# DMASS0_ECC_AGGR_0_ECCAGGR register map
Vendor: Texas Instruments
Peripheral module from a debugger description file (folder am62x).
Registers are 32-bit, access not given, reset 0x0 unless marked. A register's access mark holds for its fields unless they carry their own. Offsets are as the file gives them; lines under a group give offsets from that group; [hi:lo] are bit positions; {n}, {i} and the like mark numbered series; 'fields as' and 'values as' point back to an identical list; <NAME> marks a mode.

## DMASS0_ECC_AGGR_0_ECCAGGR
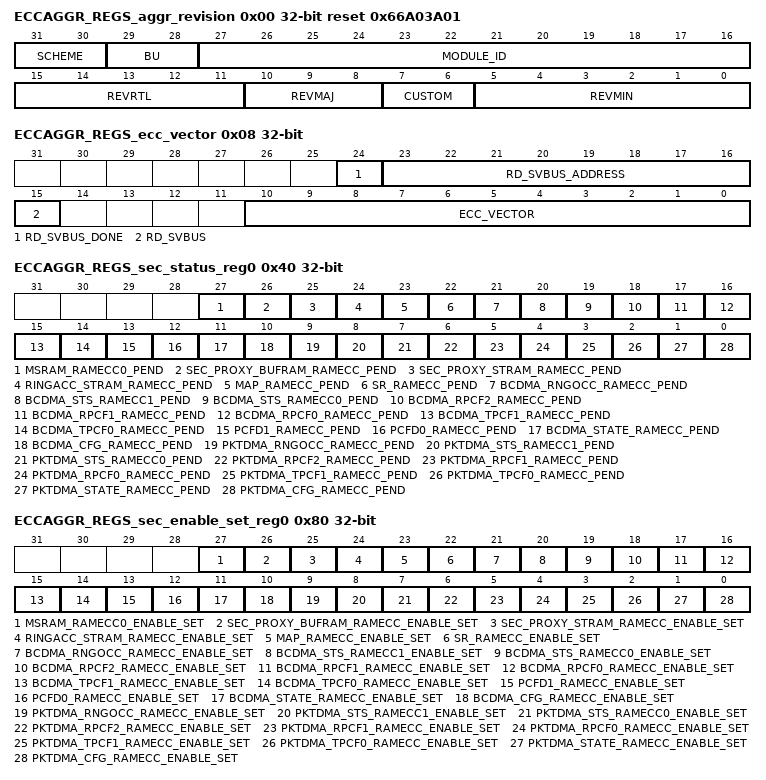
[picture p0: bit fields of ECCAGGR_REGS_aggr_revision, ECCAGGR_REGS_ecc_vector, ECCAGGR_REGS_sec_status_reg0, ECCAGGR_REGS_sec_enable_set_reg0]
0x00 ECCAGGR_REGS_aggr_revision ro reset 0x66A03A01 — Revision parameters
  [31:30] SCHEME
  [29:28] BU
  [27:16] MODULE_ID
  [15:11] REVRTL — RTL version
  [10:8] REVMAJ — Major version
  [7:6] CUSTOM — Custom version
  [5:0] REVMIN — Minor version
0x08 ECCAGGR_REGS_ecc_vector — ECC Vector Register
  [24] RD_SVBUS_DONE — Status to indicate if read on serial VBUS is complete, write of any value will clear this bit. (access R/W1TC)
  [23:16] RD_SVBUS_ADDRESS rw — Read address
  [15] RD_SVBUS — Write 1 to trigger a read on the serial VBUS (access R/W1TS)
  [10:0] ECC_VECTOR rw — Value written to select the corresponding ECC RAM for control or status
0x0C ECCAGGR_REGS_misc_status ro reset 0x1C — Misc Status
  [10:0] NUM_RAMS — Indicates the number of RAMS serviced by the ECC aggregator
0x10 ECCAGGR_REGS_reserved_svbus rw — Reference other documents that contain the ECC RAM wrapper and EDC controller serial vbus register sets.
  [31:0] DATA — Serial VBUS register data
0x3C ECCAGGR_REGS_sec_eoi_reg — EOI Register
  [0] EOI_WR — EOI Register (access R/W1TS)
0x40 ECCAGGR_REGS_sec_status_reg0 — Interrupt Status Register 0
  [27] MSRAM_RAMECC0_PEND — Interrupt Pending Status for msram_ramecc0_pend (access R/W1TS)
  [26] SEC_PROXY_BUFRAM_RAMECC_PEND — Interrupt Pending Status for sec_proxy_bufram_ramecc_pend (access R/W1TS)
  [25] SEC_PROXY_STRAM_RAMECC_PEND — Interrupt Pending Status for sec_proxy_stram_ramecc_pend (access R/W1TS)
  [24] RINGACC_STRAM_RAMECC_PEND — Interrupt Pending Status for ringacc_stram_ramecc_pend (access R/W1TS)
  [23] MAP_RAMECC_PEND — Interrupt Pending Status for map_ramecc_pend (access R/W1TS)
  [22] SR_RAMECC_PEND — Interrupt Pending Status for sr_ramecc_pend (access R/W1TS)
  [21] BCDMA_RNGOCC_RAMECC_PEND — Interrupt Pending Status for bcdma_rngocc_ramecc_pend (access R/W1TS)
  [20] BCDMA_STS_RAMECC1_PEND — Interrupt Pending Status for bcdma_sts_ramecc1_pend (access R/W1TS)
  [19] BCDMA_STS_RAMECC0_PEND — Interrupt Pending Status for bcdma_sts_ramecc0_pend (access R/W1TS)
  [18] BCDMA_RPCF2_RAMECC_PEND — Interrupt Pending Status for bcdma_rpcf2_ramecc_pend (access R/W1TS)
  [17] BCDMA_RPCF1_RAMECC_PEND — Interrupt Pending Status for bcdma_rpcf1_ramecc_pend (access R/W1TS)
  [16] BCDMA_RPCF0_RAMECC_PEND — Interrupt Pending Status for bcdma_rpcf0_ramecc_pend (access R/W1TS)
  [15] BCDMA_TPCF1_RAMECC_PEND — Interrupt Pending Status for bcdma_tpcf1_ramecc_pend (access R/W1TS)
  [14] BCDMA_TPCF0_RAMECC_PEND — Interrupt Pending Status for bcdma_tpcf0_ramecc_pend (access R/W1TS)
  [13] PCFD1_RAMECC_PEND — Interrupt Pending Status for pcfd1_ramecc_pend (access R/W1TS)
  [12] PCFD0_RAMECC_PEND — Interrupt Pending Status for pcfd0_ramecc_pend (access R/W1TS)
  [11] BCDMA_STATE_RAMECC_PEND — Interrupt Pending Status for bcdma_state_ramecc_pend (access R/W1TS)
  [10] BCDMA_CFG_RAMECC_PEND — Interrupt Pending Status for bcdma_cfg_ramecc_pend (access R/W1TS)
  [9] PKTDMA_RNGOCC_RAMECC_PEND — Interrupt Pending Status for pktdma_rngocc_ramecc_pend (access R/W1TS)
  [8] PKTDMA_STS_RAMECC1_PEND — Interrupt Pending Status for pktdma_sts_ramecc1_pend (access R/W1TS)
  [7] PKTDMA_STS_RAMECC0_PEND — Interrupt Pending Status for pktdma_sts_ramecc0_pend (access R/W1TS)
  [6] PKTDMA_RPCF2_RAMECC_PEND — Interrupt Pending Status for pktdma_rpcf2_ramecc_pend (access R/W1TS)
  [5] PKTDMA_RPCF1_RAMECC_PEND — Interrupt Pending Status for pktdma_rpcf1_ramecc_pend (access R/W1TS)
  [4] PKTDMA_RPCF0_RAMECC_PEND — Interrupt Pending Status for pktdma_rpcf0_ramecc_pend (access R/W1TS)
  [3] PKTDMA_TPCF1_RAMECC_PEND — Interrupt Pending Status for pktdma_tpcf1_ramecc_pend (access R/W1TS)
  [2] PKTDMA_TPCF0_RAMECC_PEND — Interrupt Pending Status for pktdma_tpcf0_ramecc_pend (access R/W1TS)
  [1] PKTDMA_STATE_RAMECC_PEND — Interrupt Pending Status for pktdma_state_ramecc_pend (access R/W1TS)
  [0] PKTDMA_CFG_RAMECC_PEND — Interrupt Pending Status for pktdma_cfg_ramecc_pend (access R/W1TS)
0x80 ECCAGGR_REGS_sec_enable_set_reg0 — Interrupt Enable Set Register 0
  [27] MSRAM_RAMECC0_ENABLE_SET — Interrupt Enable Set Register for msram_ramecc0_pend (access R/W1TS)
  [26] SEC_PROXY_BUFRAM_RAMECC_ENABLE_SET — Interrupt Enable Set Register for sec_proxy_bufram_ramecc_pend (access R/W1TS)
  [25] SEC_PROXY_STRAM_RAMECC_ENABLE_SET — Interrupt Enable Set Register for sec_proxy_stram_ramecc_pend (access R/W1TS)
  [24] RINGACC_STRAM_RAMECC_ENABLE_SET — Interrupt Enable Set Register for ringacc_stram_ramecc_pend (access R/W1TS)
  [23] MAP_RAMECC_ENABLE_SET — Interrupt Enable Set Register for map_ramecc_pend (access R/W1TS)
  [22] SR_RAMECC_ENABLE_SET — Interrupt Enable Set Register for sr_ramecc_pend (access R/W1TS)
  [21] BCDMA_RNGOCC_RAMECC_ENABLE_SET — Interrupt Enable Set Register for bcdma_rngocc_ramecc_pend (access R/W1TS)
  [20] BCDMA_STS_RAMECC1_ENABLE_SET — Interrupt Enable Set Register for bcdma_sts_ramecc1_pend (access R/W1TS)
  [19] BCDMA_STS_RAMECC0_ENABLE_SET — Interrupt Enable Set Register for bcdma_sts_ramecc0_pend (access R/W1TS)
  [18] BCDMA_RPCF2_RAMECC_ENABLE_SET — Interrupt Enable Set Register for bcdma_rpcf2_ramecc_pend (access R/W1TS)
  [17] BCDMA_RPCF1_RAMECC_ENABLE_SET — Interrupt Enable Set Register for bcdma_rpcf1_ramecc_pend (access R/W1TS)
  [16] BCDMA_RPCF0_RAMECC_ENABLE_SET — Interrupt Enable Set Register for bcdma_rpcf0_ramecc_pend (access R/W1TS)
  [15] BCDMA_TPCF1_RAMECC_ENABLE_SET — Interrupt Enable Set Register for bcdma_tpcf1_ramecc_pend (access R/W1TS)
  [14] BCDMA_TPCF0_RAMECC_ENABLE_SET — Interrupt Enable Set Register for bcdma_tpcf0_ramecc_pend (access R/W1TS)
  [13] PCFD1_RAMECC_ENABLE_SET — Interrupt Enable Set Register for pcfd1_ramecc_pend (access R/W1TS)
  [12] PCFD0_RAMECC_ENABLE_SET — Interrupt Enable Set Register for pcfd0_ramecc_pend (access R/W1TS)
  [11] BCDMA_STATE_RAMECC_ENABLE_SET — Interrupt Enable Set Register for bcdma_state_ramecc_pend (access R/W1TS)
  [10] BCDMA_CFG_RAMECC_ENABLE_SET — Interrupt Enable Set Register for bcdma_cfg_ramecc_pend (access R/W1TS)
  [9] PKTDMA_RNGOCC_RAMECC_ENABLE_SET — Interrupt Enable Set Register for pktdma_rngocc_ramecc_pend (access R/W1TS)
  [8] PKTDMA_STS_RAMECC1_ENABLE_SET — Interrupt Enable Set Register for pktdma_sts_ramecc1_pend (access R/W1TS)
  [7] PKTDMA_STS_RAMECC0_ENABLE_SET — Interrupt Enable Set Register for pktdma_sts_ramecc0_pend (access R/W1TS)
  [6] PKTDMA_RPCF2_RAMECC_ENABLE_SET — Interrupt Enable Set Register for pktdma_rpcf2_ramecc_pend (access R/W1TS)
  [5] PKTDMA_RPCF1_RAMECC_ENABLE_SET — Interrupt Enable Set Register for pktdma_rpcf1_ramecc_pend (access R/W1TS)
  [4] PKTDMA_RPCF0_RAMECC_ENABLE_SET — Interrupt Enable Set Register for pktdma_rpcf0_ramecc_pend (access R/W1TS)
  [3] PKTDMA_TPCF1_RAMECC_ENABLE_SET — Interrupt Enable Set Register for pktdma_tpcf1_ramecc_pend (access R/W1TS)
  [2] PKTDMA_TPCF0_RAMECC_ENABLE_SET — Interrupt Enable Set Register for pktdma_tpcf0_ramecc_pend (access R/W1TS)
  [1] PKTDMA_STATE_RAMECC_ENABLE_SET — Interrupt Enable Set Register for pktdma_state_ramecc_pend (access R/W1TS)
  [0] PKTDMA_CFG_RAMECC_ENABLE_SET — Interrupt Enable Set Register for pktdma_cfg_ramecc_pend (access R/W1TS)
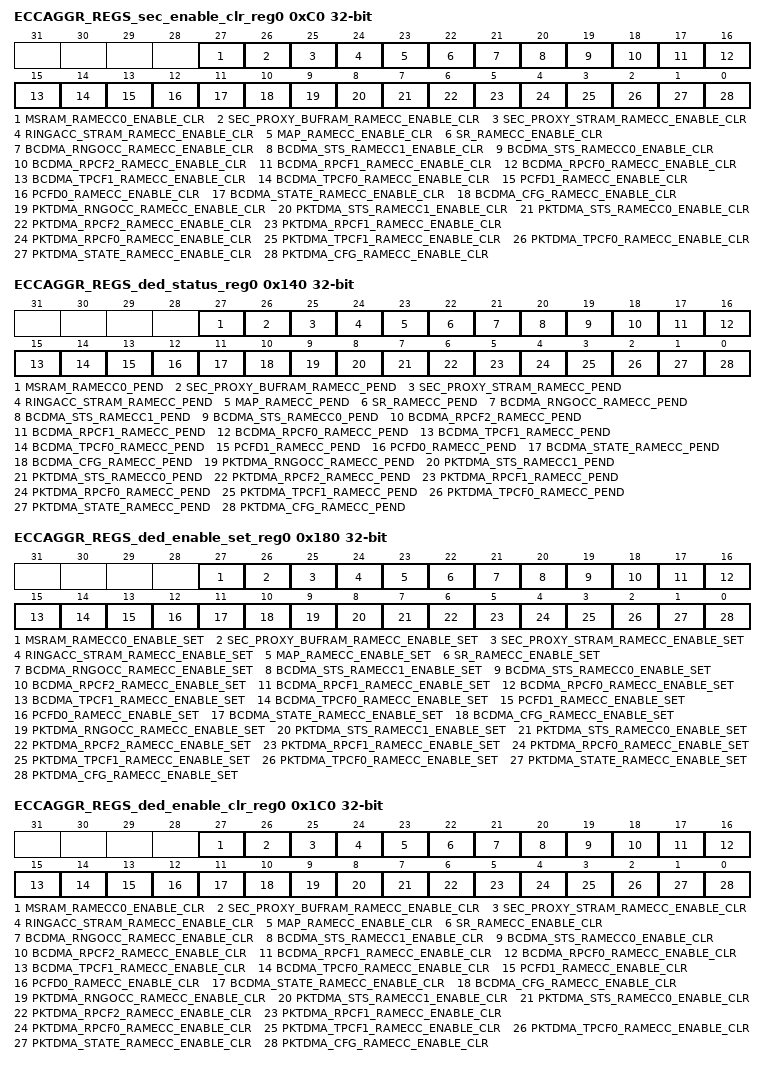
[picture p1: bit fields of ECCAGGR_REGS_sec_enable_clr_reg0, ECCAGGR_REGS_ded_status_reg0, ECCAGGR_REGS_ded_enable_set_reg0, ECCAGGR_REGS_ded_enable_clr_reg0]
0xC0 ECCAGGR_REGS_sec_enable_clr_reg0 — Interrupt Enable Clear Register 0
  [27] MSRAM_RAMECC0_ENABLE_CLR — Interrupt Enable Clear Register for msram_ramecc0_pend (access R/W1TC)
  [26] SEC_PROXY_BUFRAM_RAMECC_ENABLE_CLR — Interrupt Enable Clear Register for sec_proxy_bufram_ramecc_pend (access R/W1TC)
  [25] SEC_PROXY_STRAM_RAMECC_ENABLE_CLR — Interrupt Enable Clear Register for sec_proxy_stram_ramecc_pend (access R/W1TC)
  [24] RINGACC_STRAM_RAMECC_ENABLE_CLR — Interrupt Enable Clear Register for ringacc_stram_ramecc_pend (access R/W1TC)
  [23] MAP_RAMECC_ENABLE_CLR — Interrupt Enable Clear Register for map_ramecc_pend (access R/W1TC)
  [22] SR_RAMECC_ENABLE_CLR — Interrupt Enable Clear Register for sr_ramecc_pend (access R/W1TC)
  [21] BCDMA_RNGOCC_RAMECC_ENABLE_CLR — Interrupt Enable Clear Register for bcdma_rngocc_ramecc_pend (access R/W1TC)
  [20] BCDMA_STS_RAMECC1_ENABLE_CLR — Interrupt Enable Clear Register for bcdma_sts_ramecc1_pend (access R/W1TC)
  [19] BCDMA_STS_RAMECC0_ENABLE_CLR — Interrupt Enable Clear Register for bcdma_sts_ramecc0_pend (access R/W1TC)
  [18] BCDMA_RPCF2_RAMECC_ENABLE_CLR — Interrupt Enable Clear Register for bcdma_rpcf2_ramecc_pend (access R/W1TC)
  [17] BCDMA_RPCF1_RAMECC_ENABLE_CLR — Interrupt Enable Clear Register for bcdma_rpcf1_ramecc_pend (access R/W1TC)
  [16] BCDMA_RPCF0_RAMECC_ENABLE_CLR — Interrupt Enable Clear Register for bcdma_rpcf0_ramecc_pend (access R/W1TC)
  [15] BCDMA_TPCF1_RAMECC_ENABLE_CLR — Interrupt Enable Clear Register for bcdma_tpcf1_ramecc_pend (access R/W1TC)
  [14] BCDMA_TPCF0_RAMECC_ENABLE_CLR — Interrupt Enable Clear Register for bcdma_tpcf0_ramecc_pend (access R/W1TC)
  [13] PCFD1_RAMECC_ENABLE_CLR — Interrupt Enable Clear Register for pcfd1_ramecc_pend (access R/W1TC)
  [12] PCFD0_RAMECC_ENABLE_CLR — Interrupt Enable Clear Register for pcfd0_ramecc_pend (access R/W1TC)
  [11] BCDMA_STATE_RAMECC_ENABLE_CLR — Interrupt Enable Clear Register for bcdma_state_ramecc_pend (access R/W1TC)
  [10] BCDMA_CFG_RAMECC_ENABLE_CLR — Interrupt Enable Clear Register for bcdma_cfg_ramecc_pend (access R/W1TC)
  [9] PKTDMA_RNGOCC_RAMECC_ENABLE_CLR — Interrupt Enable Clear Register for pktdma_rngocc_ramecc_pend (access R/W1TC)
  [8] PKTDMA_STS_RAMECC1_ENABLE_CLR — Interrupt Enable Clear Register for pktdma_sts_ramecc1_pend (access R/W1TC)
  [7] PKTDMA_STS_RAMECC0_ENABLE_CLR — Interrupt Enable Clear Register for pktdma_sts_ramecc0_pend (access R/W1TC)
  [6] PKTDMA_RPCF2_RAMECC_ENABLE_CLR — Interrupt Enable Clear Register for pktdma_rpcf2_ramecc_pend (access R/W1TC)
  [5] PKTDMA_RPCF1_RAMECC_ENABLE_CLR — Interrupt Enable Clear Register for pktdma_rpcf1_ramecc_pend (access R/W1TC)
  [4] PKTDMA_RPCF0_RAMECC_ENABLE_CLR — Interrupt Enable Clear Register for pktdma_rpcf0_ramecc_pend (access R/W1TC)
  [3] PKTDMA_TPCF1_RAMECC_ENABLE_CLR — Interrupt Enable Clear Register for pktdma_tpcf1_ramecc_pend (access R/W1TC)
  [2] PKTDMA_TPCF0_RAMECC_ENABLE_CLR — Interrupt Enable Clear Register for pktdma_tpcf0_ramecc_pend (access R/W1TC)
  [1] PKTDMA_STATE_RAMECC_ENABLE_CLR — Interrupt Enable Clear Register for pktdma_state_ramecc_pend (access R/W1TC)
  [0] PKTDMA_CFG_RAMECC_ENABLE_CLR — Interrupt Enable Clear Register for pktdma_cfg_ramecc_pend (access R/W1TC)
0x13C ECCAGGR_REGS_ded_eoi_reg — EOI Register
  [0] EOI_WR — EOI Register (access R/W1TS)
0x140 ECCAGGR_REGS_ded_status_reg0 — Interrupt Status Register 0
  fields as ECCAGGR_REGS_sec_status_reg0
0x180 ECCAGGR_REGS_ded_enable_set_reg0 — Interrupt Enable Set Register 0
  fields as ECCAGGR_REGS_sec_enable_set_reg0
0x1C0 ECCAGGR_REGS_ded_enable_clr_reg0 — Interrupt Enable Clear Register 0
  fields as ECCAGGR_REGS_sec_enable_clr_reg0
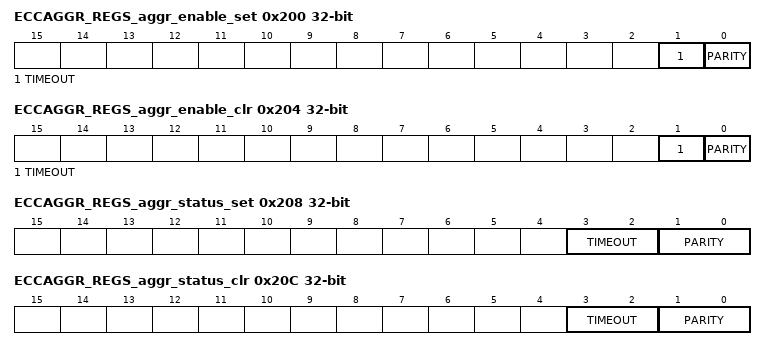
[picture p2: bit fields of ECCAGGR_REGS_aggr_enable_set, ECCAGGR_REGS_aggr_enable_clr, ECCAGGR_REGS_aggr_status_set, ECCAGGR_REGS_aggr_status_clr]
0x200 ECCAGGR_REGS_aggr_enable_set — AGGR interrupt enable set Register
  [1] TIMEOUT — interrupt enable set for svbus timeout errors (access R/W1TS)
  [0] PARITY — interrupt enable set for parity errors (access R/W1TS)
0x204 ECCAGGR_REGS_aggr_enable_clr — AGGR interrupt enable clear Register
  [1] TIMEOUT — interrupt enable clear for svbus timeout errors (access R/W1TC)
  [0] PARITY — interrupt enable clear for parity errors (access R/W1TC)
0x208 ECCAGGR_REGS_aggr_status_set — AGGR interrupt status set Register
  [3:2] TIMEOUT — interrupt status set for svbus timeout errors (access R/WI)
  [1:0] PARITY — interrupt status set for parity errors (access R/WI)
0x20C ECCAGGR_REGS_aggr_status_clr — AGGR interrupt status clear Register
  [3:2] TIMEOUT — interrupt status clear for svbus timeout errors (access R/WD)
  [1:0] PARITY — interrupt status clear for parity errors (access R/WD)
